AUTOSAR XML (schema 4-2-1)
package /RootP_ASWC_SATELLITE_CORE1_AppASILA
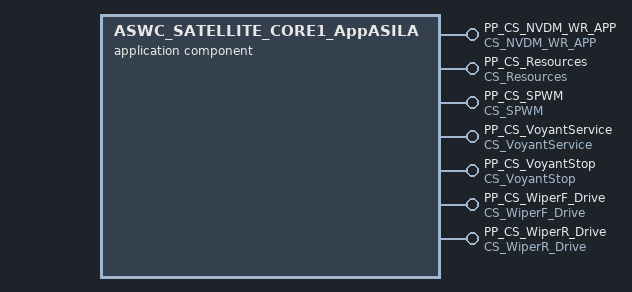
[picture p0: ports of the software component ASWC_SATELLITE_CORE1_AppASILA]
  application sw component type ASWC_SATELLITE_CORE1_AppASILA
    7 x provide port:
      PP_CS_NVDM_WR_APP: server-com-spec{operation=NvDM_WrApp_Block, queue-length=1}, provided-interface=CS_NVDM_WR_APP
      PP_CS_Resources: server-com-spec{operation=Request, queue-length=1}, provided-interface=CS_Resources
      PP_CS_SPWM: server-com-spec{operation=Set, queue-length=1}, provided-interface=CS_SPWM
      PP_CS_VoyantService: server-com-spec{operation=Piloter, queue-length=1}, provided-interface=CS_VoyantService
      PP_CS_VoyantStop: server-com-spec{operation=Piloter, queue-length=1}, provided-interface=CS_VoyantStop
      PP_CS_WiperF_Drive: server-com-spec{operation=OP_SET, queue-length=1}, provided-interface=CS_WiperF_Drive
      PP_CS_WiperR_Drive: server-com-spec{operation=OP_SET, queue-length=1}, provided-interface=CS_WiperR_Drive
    behavior IB_ASWC_SATELLITE_CORE1_AppASILA: handle-termination-and-restart=NO-SUPPORT
      7 x operation invoked event:
        CS_NVDM_WR_APP_NvDM_WrApp_Block_OIE_CORE1_AppASILA: start-on-event=RUNS_NVDM_WR_APP_NvDM_WrApp_Block_CORE1_AppASILA, operation=PP_CS_NVDM_WR_APP.NvDM_WrApp_Block
        CS_Resources_Request_OIE_CORE1_AppASILA: start-on-event=RUNS_Resources_Request_CORE1_AppASILA, operation=PP_CS_Resources.Request
        CS_SPWM_Set_OIE_CORE1_AppASILA: start-on-event=RUNS_SPWM_Set_CORE1_AppASILA, operation=PP_CS_SPWM.Set
        CS_VoyantService_Piloter_OIE_CORE1_AppASILA: start-on-event=RUNS_VoyantService_Piloter_CORE1_AppASILA, operation=PP_CS_VoyantService.Piloter
        CS_VoyantStop_Piloter_OIE_CORE1_AppASILA: start-on-event=RUNS_VoyantStop_Piloter_CORE1_AppASILA, operation=PP_CS_VoyantStop.Piloter
        CS_WiperF_Drive_OP_SET_OIE_CORE1_AppASILA: start-on-event=RUNS_WiperF_Drive_OP_SET_CORE1_AppASILA, operation=PP_CS_WiperF_Drive.OP_SET
        CS_WiperR_Drive_OP_SET_OIE_CORE1_AppASILA: start-on-event=RUNS_WiperR_Drive_OP_SET_CORE1_AppASILA, operation=PP_CS_WiperR_Drive.OP_SET
      7 x runnable, all with can-be-invoked-concurrently=true:
        RUNS_NVDM_WR_APP_NvDM_WrApp_Block_CORE1_AppASILA
        RUNS_Resources_Request_CORE1_AppASILA
        RUNS_SPWM_Set_CORE1_AppASILA
        RUNS_VoyantService_Piloter_CORE1_AppASILA
        RUNS_VoyantStop_Piloter_CORE1_AppASILA
        RUNS_WiperF_Drive_OP_SET_CORE1_AppASILA
        RUNS_WiperR_Drive_OP_SET_CORE1_AppASILA
  swc implementation ASWC_SATELLITE_CORE1_AppASILA_Impl: programming-language=C, sw-version=1.0.0, vendor-id=0, behavior=IB_ASWC_SATELLITE_CORE1_AppASILA
    code-descriptors:
      code SRC: artifact-descriptors=autosar-engineering-object={short-label=EngObject, category=SWSRC}
    resource consumption Resources
      memory section CODE: sw-addrmethod=CODE_ASWC_SATELLITE_CORE1_AppASILA
  sw addr method CODE_ASWC_SATELLITE_CORE1_AppASILA: memory-allocation-keyword-policy=ADDR-METHOD-SHORT-NAME-AND-ALIGNMENT, section-type=CODE
